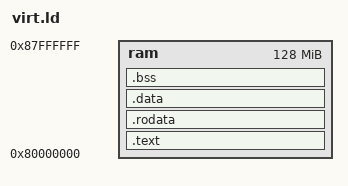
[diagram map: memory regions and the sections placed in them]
OUTPUT_ARCH( "riscv" )
ENTRY( _start ) /* entry point is defined in boot.s */

/* virt RAM starts at 0x80000000 (see .dts generated by `./qemu-ryos.sh -d`)
 * specify 128 megabytes, which should match the QEMU -m flag
 */
MEMORY
{
  ram : ORIGIN = 0x80000000, LENGTH = 128M
}

SECTIONS
{
  .text : {
    PROVIDE(__text_start = .);
    *(.text.init) /* ensure that .text.init (boot.s) is precicely at ORIGIN(ram) */
    *(.text .text.*)
    PROVIDE(__text_end = .);
  } >ram

  PROVIDE(__global_pointer = .);

  .rodata : {
    PROVIDE(__rodata_start = .);
    . = ALIGN(16);
    *(.srodata .srodata.*) /* do not need to distinguish this from .rodata */
    . = ALIGN(16);
    *(.rodata .rodata.*)
    PROVIDE(__rodata_end = .);
  } >ram

  .data : {
    PROVIDE(__data_start = .);
    . = ALIGN(16);
    *(.sdata .sdata.*) /* do not need to distinguish this from .data */
    . = ALIGN(16);
    *(.data .data.*)
    PROVIDE(__data_end = .);
  } >ram

  .bss : {
    . = ALIGN(16);
    PROVIDE(__bss_start = .);
    *(.sbss .sbss.*) /* do not need to distinguish this from .bss */
    . = ALIGN(16);
    *(.bss .bss.*)
    PROVIDE(__bss_end = .);
  } >ram

  PROVIDE(__memory_start = ORIGIN(ram));
  PROVIDE(__memory_end = ORIGIN(ram) + LENGTH(ram));

  PROVIDE(__stack_start = __bss_end);
  PROVIDE(__stack_end = __stack_start + 0x40000); /* 64K * 4 harts = 256K */

  PROVIDE(__heap_start = __stack_end);
  PROVIDE(__heap_end = __memory_end);
}

